# REF_A_367.0 register map
Vendor: Texas Instruments
Peripheral module from a debugger description file (folder msp430).
Registers are 16-bit, access per field, no defined reset value unless marked. A register's access mark holds for its fields unless they carry their own. Offsets are as the file gives them; lines under a group give offsets from that group; [hi:lo] are bit positions; {n}, {i} and the like mark numbered series; 'fields as' and 'values as' point back to an identical list; <NAME> marks a mode.

## REF_A
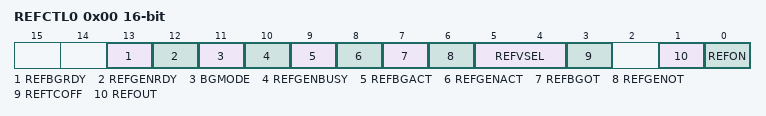
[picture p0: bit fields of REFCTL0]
0x00 REFCTL0 — REF Control Register 0
  [13] REFBGRDY ro — Buffered bandgap voltage ready status
    0=Buffered bandgap voltage is not ready to be used; 1=Buffered bandgap voltage is ready to be used
  [12] REFGENRDY ro — Variable reference voltage ready status
    0=Reference voltage output is not ready to be used; 1=Reference voltage output is ready to be used
  [11] BGMODE ro — Bandgap mode
    0=Static mode; 1=Sampled mode
  [10] REFGENBUSY ro — Reference generator busy
    0=Reference generator not busy; 1=Reference generator busy
  [9] REFBGACT ro — Reference bandgap active
    0=Reference bandgap buffer not active; 1=Reference bandgap buffer active
  [8] REFGENACT ro — Reference generator active
    0=Reference generator not active; 1=Reference generator active
  [7] REFBGOT rw — Bandgap and bandgap buffer one-time trigger
    0=No trigger; 1=Generation of the bandgap voltage is started by writing 1 or by a hardware trigger
  [6] REFGENOT rw — Reference generator one-time trigger
    0=No trigger; 1=Generation of the reference voltage is started by writing 1 or by a hardware trigger
  [5:4] REFVSEL rw — Reference voltage level select
    0=1.2 V available when reference requested or REFON = 1; 1=2.0 V available when reference requested or REFON = 1; 2=2.5 V available when reference requested or REFON = 1; 3=2.5 V available when reference requested or REFON = 1
  [3] REFTCOFF rw — Temperature sensor disabled
    0=Temperature sensor enabled; 1=Temperature sensor disabled to save power
  [1] REFOUT rw — Reference output buffer
    0=Reference output not available externally; 1=Reference output available externally. If ADC14REFBURST = 0, output is available continuously. If ADC14REFBURST = 1, output is available only during an ADC14 conversion.
  [0] REFON rw — Reference enable
    0=Disables reference if no other reference requests are pending; 1=Enables reference in static mode
